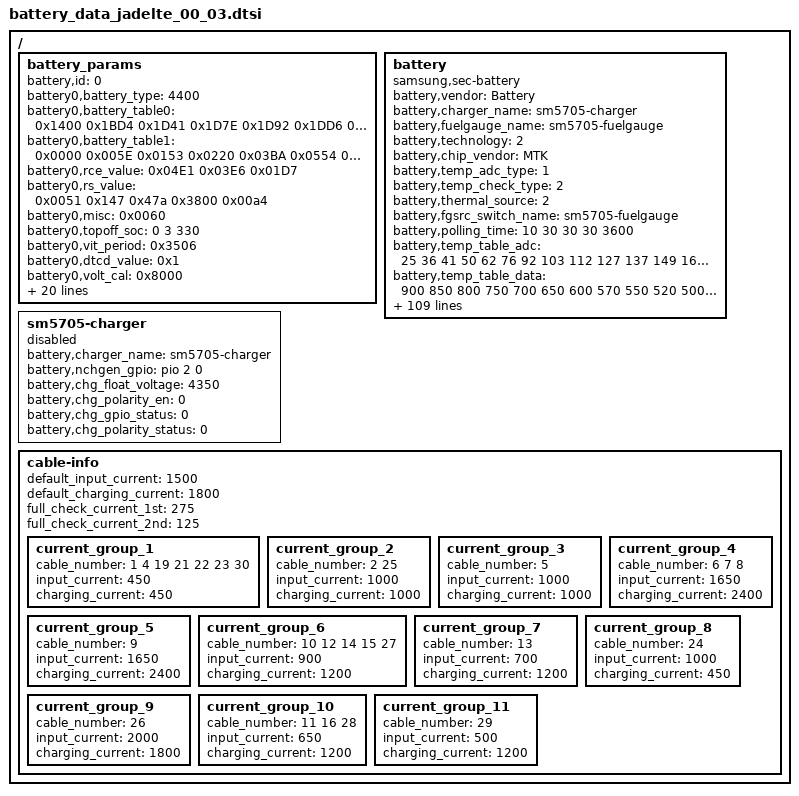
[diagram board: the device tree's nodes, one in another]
/*
 * JADELTE Battery parameters device tree file for board IDs 00-03
 *
 * Copyright (C) 2017 Samsung Electronics, Inc.
 *
 * This program is free software; you can redistribute it and/or
 * modify it under the terms of the GNU General Public License
 * as published by the Free Software Foundation; either version 2
 * of the License, or (at your option) any later version.
 *
 * This program is distributed in the hope that it will be useful,
 * but WITHOUT ANY WARRANTY; without even the implied warranty of
 * MERCHANTABILITY or FITNESS FOR A PARTICULAR PURPOSE.  See the
 * GNU General Public License for more details.
 *
 * You should have received a copy of the GNU General Public License
 * along with this program. If not, see <http://www.gnu.org/licenses/>.
 *
 */

/ {
	battery_params {
		battery,id = <0>; /* -1 means auto, detected by F/G */
		battery0,battery_type = <4400>; /* 4200 4350 4400 */
		battery0,battery_table0 = <0x1400 0x1BD4 0x1D41 0x1D7E 0x1D92 0x1DD6 0x1E29 0x1E88 0x1EE9 0x1F83 0x1FD4 0x202B 0x20C5 0x21A7 0x229F 0x2400>;
		battery0,battery_table1 = <0x0000 0x005E 0x0153 0x0220 0x03BA 0x0554 0x0880 0x0D46 0x107A 0x12D9 0x1473 0x160D 0x186C 0x1BA0 0x1ECC 0x1ED4>;
		battery0,rce_value = <0x04E1 0x03E6 0x01D7>;
		battery0,rs_value = <0x0051 0x147 0x47a 0x3800 0x00a4>; /*rs p_mix_factor n_mix_factor max min*/
		battery0,misc = <0x0060>;
		battery0,topoff_soc = <0 3 330>; /*enable soc current*/
		battery0,vit_period = <0x3506>;
		battery0,dtcd_value = <0x1>;
		battery0,volt_cal = <0x8000>;
		battery0,curr_offset = <1 0x0000>; /*en_auto offset*/
		battery0,p_curr_cal = <0x0094>;
		battery0,n_curr_cal = <0x009F>;
		battery0,mix_value = <0x0503 0x0004>; /*mix_rate init_blank*/
		battery0,temp_std = <25>;
		battery0,temp_cal = <1 6 1 11 (-1) 1 6 1 9 1>; /* en_h, p_de, p_fa, n_de, n_fa, en_l, p_de, p_fa, n_de, n_fa, */
		battery0,ext_temp_cal = <0 2 1 2 1 1 2 3 2 3>; /* en_h, p_de, p_fa, n_de, n_fa, en_l, p_de, p_fa, n_de, n_fa, */
		battery0,temp_volcal = <1 15 1>; /* en, temp, cal */
		battery0,temp_offset = <1 11 1 1 8 (-1)>; /* en_high level offset en_low level offset */
		battery0,cycle_cfg = <7 1 3>; /*high_limit low_limit cntl*/
		battery0,curr_lcal = <0 0x8888 0x8888 0x8888>;
		battery0,tem_poff = <3400 50 3300 50>;
		battery0,v_offset_cancel = <1 0 100 10>; /* en_p, en_n, level, mohm */
		battery0,v_alarm = <3200>;
		battery0,full_offset = <20 4>; /*margin extra_offset*/
		battery0,v_max_table = <0x2274 0x223D 0x2214 0x21EB 0x219C>; /* For long life of battery */
		battery0,q_max_table = <0x1915 0x18A3 0x1830 0x17BE 0x16A0>; /* For long life of battery */
		battery0,data_ver = <0x01>;
	};

	battery {
		status = "okay";
		compatible = "samsung,sec-battery";

		pinctrl-names = "default";

		battery,vendor = "Battery";
		battery,charger_name = "sm5705-charger";
		battery,fuelgauge_name = "sm5705-fuelgauge";
		battery,technology = <2>; /* POWER_SUPPLY_TECHNOLOGY_LION */

		battery,chip_vendor = "MTK";
		battery,temp_adc_type = <1>; /* SEC_BATTERY_ADC_TYPE_AP */

		battery,temp_check_type = <2>; /* SEC_BATTERY_TEMP_CHECK_TEMP */

		battery,thermal_source = <2>; /* SEC_BATTERY_THERMAL_SOURCE_ADC */

		battery,fgsrc_switch_name = "sm5705-fuelgauge";

		battery,polling_time = <10 30 30 30 3600>;

		battery,temp_table_adc = <
					25 36 41 50 62 76 92 103 112 127
					137 149 168 182 197 220 238 257	301
					365 409	441 475	530 570	633 677	745
					793 864	907 986	1117 1241 1358
					>;

		battery,temp_table_data = <
					900 850 800 750 700 650 600 570
					550 520 500 480 450 430 410 380
					360 340 300 250 220 200 180 150
					130 100 80 50 30 0 (-20) (-50) (-100) (-150) (-200)
					>;

		battery,adc_check_count = <5>;

		battery,cable_check_type = <4>; /* SEC_BATTERY_CABLE_CHECK_PSY */
		battery,cable_source_type = <1>; /* SEC_BATTERY_CABLE_SOURCE_EXTERNAL */
		battery,polling_type = <1>; /* SEC_BATTERY_MONITOR_ALARM */
		battery,monitor_initial_count = <0>;

		battery,battery_check_type = <0>; /* SEC_BATTERY_CHECK_NONE */
		battery,check_count = <0>;
		battery,check_adc_max = <1440>;
		battery,check_adc_min = <0>;

		battery,ovp_uvlo_check_type = <3>; /* SEC_BATTERY_OVP_UVLO_CHGPOLLING */

		battery,temp_check_count = <1>;
		battery,temp_highlimit_threshold_event = <800>;
		battery,temp_highlimit_recovery_event = <750>;
		battery,temp_high_threshold_event = <500>;
		battery,temp_high_recovery_event = <450>;
		battery,temp_low_threshold_event = <(0)>;
		battery,temp_low_recovery_event = <50>;
		battery,temp_highlimit_threshold_normal = <800>;
		battery,temp_highlimit_recovery_normal = <750>;
		battery,temp_high_threshold_normal = <500>;
		battery,temp_high_recovery_normal = <450>;
		battery,temp_low_threshold_normal = <(0)>;
		battery,temp_low_recovery_normal = <50>;
		battery,temp_highlimit_threshold_lpm = <800>;
		battery,temp_highlimit_recovery_lpm = <750>;
		battery,temp_high_threshold_lpm = <500>;
		battery,temp_high_recovery_lpm = <450>;
		battery,temp_low_threshold_lpm = <(0)>;
		battery,temp_low_recovery_lpm = <50>;
		battery,wpc_high_threshold_normal = <450>;
		battery,wpc_high_recovery_normal = <400>;
		battery,wpc_low_threshold_normal = <(0)>;
		battery,wpc_low_recovery_normal = <50>;
		battery,full_check_type = <2>; /* SEC_BATTERY_FULLCHARGED_FG_CURRENT */
		battery,full_check_type_2nd = <2>; /* SEC_BATTERY_FULLCHARGED_FG_CURRENT */
		battery,full_check_count = <1>;
		battery,chg_gpio_full_check = <0>;
		battery,chg_polarity_full_check = <1>;

		battery,chg_high_temp = <460>;
		battery,chg_high_temp_recovery = <440>;
		battery,chg_input_limit_current = <1000>;
		battery,chg_charging_limit_current = <1250>; 

		battery,wpc_high_temp = <410>;
		battery,wpc_high_temp_recovery = <400>;
		battery,wpc_charging_limit_current = <450>;
		battery,wpc_lcd_on_high_temp = <430>;
		battery,wpc_lcd_on_high_temp_rec = <300>;

		battery,sleep_mode_limit_current = <500>;
		battery,wc_full_input_limit_current = <100>;
		battery,wc_cv_current = <820>;
		battery,wc_cv_pack_current = <630>;

		battery,mix_high_temp = <420>;
		battery,mix_high_chg_temp = <500>;
		battery,mix_high_temp_recovery = <390>;

		/* SEC_BATTERY_FULL_CONDITION_SOC |
		   SEC_BATTERY_FULL_CONDITION_NOTIMEFULL |
		   SEC_BATTERY_FULL_CONDITION_VCELL */
		battery,full_condition_type = <13>;
		battery,full_condition_soc = <93>;
		battery,full_condition_vcell = <4250>;

		battery,recharge_check_count = <1>;
		battery,recharge_condition_type = <4>; /* SEC_BATTERY_RECHARGE_CONDITION_VCELL */
		battery,recharge_condition_soc = <98>;
		battery,recharge_condition_vcell = <4300>;

		battery,charging_total_time = <14400>;
		battery,hv_charging_total_time = <10800>;
		battery,normal_charging_total_time = <18000>;
		battery,usb_charging_total_time = <36000>;
		battery,recharging_total_time = <5400>;
		battery,charging_reset_time = <0>;

		battery,chg_float_voltage = <4350>;

		battery,swelling_high_temp_block = <410>;
		battery,swelling_high_temp_recov = <360>;
		battery,swelling_low_temp_block_1st = <150>;
		battery,swelling_low_temp_recov_1st = <200>;
		battery,swelling_low_temp_block_2nd = <50>;
		battery,swelling_low_temp_recov_2nd = <100>;

		battery,swelling_low_temp_current = <700>;	/* 0.3C */
		battery,swelling_low_temp_topoff = <150>;	/* 0.05C */
		battery,swelling_high_temp_current = <1050>;	/* 0.45C */
		battery,swelling_high_temp_topoff = <150>;	/* 0.05C */
		battery,swelling_wc_high_temp_current = <700>;	/* 0.3C */
		battery,swelling_wc_low_temp_current = <700>;	/* 0.3C */

		battery,swelling_drop_float_voltage = <4150>;
		battery,swelling_high_rechg_voltage = <4000>;
		battery,swelling_low_rechg_voltage = <4000>;

		battery,siop_event_check_type = <1>;
		battery,siop_call_cv_current = <330>;
		battery,siop_call_cc_current = <330>;

		battery,siop_input_limit_current = <1200>;
		battery,siop_charging_limit_current = <1000>;
		battery,siop_hv_input_limit_current = <500>;
		battery,siop_hv_charging_limit_current = <1000>;

		battery,siop_wireless_input_limit_current = <600>;
		battery,siop_wireless_charging_limit_current = <700>;
		battery,siop_hv_wireless_input_limit_current = <600>;
		battery,siop_hv_wireless_charging_limit_current = <700>;

		battery,ttf_hv_charge_current = <2150>;
		battery,ttf_hv_wireless_charge_current = <1150>;

		battery,pd_charging_charge_power = <15000>;
		battery,max_charging_current = <2150>;
		battery,battery_full_capacity = <3000>;

		/* cycle, chg_float_voltage, recharge_condition_vcell, full_condition_vcell, full_condition_soc */
		battery,age_data = <0 4350 4300 4250 93
				200 4330 4280 4230 89
				250 4310 4260 4210 85
				300 4290 4240 4190 80
				1000 4240 4190 4140 75>;

		battery,max_input_voltage = <12000>; /* mV */
		battery,max_input_current = <3000>;  /* mA */

		battery,standard_curr = <2100>;
		battery,expired_time = <10800>;
		battery,recharging_expired_time = <5400>;
	};

	sm5705-charger {
		status = "disable";
		/* Charger */
		battery,charger_name = "sm5705-charger";
		battery,nchgen_gpio = <&pio 2 0>;
		battery,chg_float_voltage = <4350>;

		battery,chg_polarity_en = <0>;
		battery,chg_gpio_status = <0>;
		battery,chg_polarity_status = <0>;
	};

/* sec_battery_cable
 *   0	UNKNOWN,
 *   1	NONE,
 *   2	PREPARE_TA,
 *   3	TA,
 *   4	USB,
 *   5	USB_CDP,
 *   6	9V_TA,
 *   7	9V_ERR,
 *   8	9V_UNKNOWN,
 *   9	12V_TA,
 *  10	WIRELESS,
 *  11	HV_WIRELESS,
 *  12	PMA_WIRELESS,
 *  13	WIRELESS_PACK,
 *  14	WIRELESS_PACK_TA,
 *  15	WIRELESS_STAND,
 *  16	WIRELESS_HV_STAND,
 *  17	QC20,
 *  18	QC30,
 *  19	PDIC,
 *  20	UARTOFF,
 *  21	OTG,
 *  22	LAN_HUB,
 *  23	POWER_SHARING,
 *  24	HMT_CONNECTED,
 *  25	HMT_CHARGE,
 *  26	HV_TA_CHG_LIMIT,
 *  27	WIRELESS_VEHICLE,
 *  28	WIRELESS_HV_VEHICLE,
 *  29	PREPARE_WIRELESS_HV,
 *  30	TIMEOUT,
 *  31	CABLE_MAX,
*/
	cable-info{
		default_input_current = <1500>;
		default_charging_current = <1800>;
		full_check_current_1st = <275>;
		full_check_current_2nd = <125>;

		current_group_1 {
			cable_number = <1 4 19 21 22 23 30>;
			input_current = <450>;
			charging_current = <450>;
		};
		current_group_2 {
			cable_number = <2 25>;
			input_current = <1000>;
			charging_current = <1000>;
		};
		current_group_3 {
			cable_number = <5>;
			input_current = <1000>;
			charging_current = <1000>;
		};
		current_group_4 {
			cable_number = <6 7 8>;
			input_current = <1650>;
			charging_current = <2400>;
		};
		current_group_5 {
			cable_number = <9>;
			input_current = <1650>;
			charging_current = <2400>;
		};
		current_group_6 {
			cable_number = <10 12 14 15 27>;
			input_current = <900>;
			charging_current = <1200>;
		};
		current_group_7 {
			cable_number = <13>;
			input_current = <700>;
			charging_current = <1200>;
		};
		current_group_8 {
			cable_number = <24>;
			input_current = <1000>;
			charging_current = <450>;
		};
		current_group_9 {
			cable_number = <26>;
			input_current = <2000>;
			charging_current = <1800>;
		};
		current_group_10 {
			cable_number = <11 16 28>;
			input_current = <650>;
			charging_current = <1200>;
		};
		current_group_11 {
			cable_number = <29>;
			input_current = <500>;
			charging_current = <1200>;
		};
	};
};
